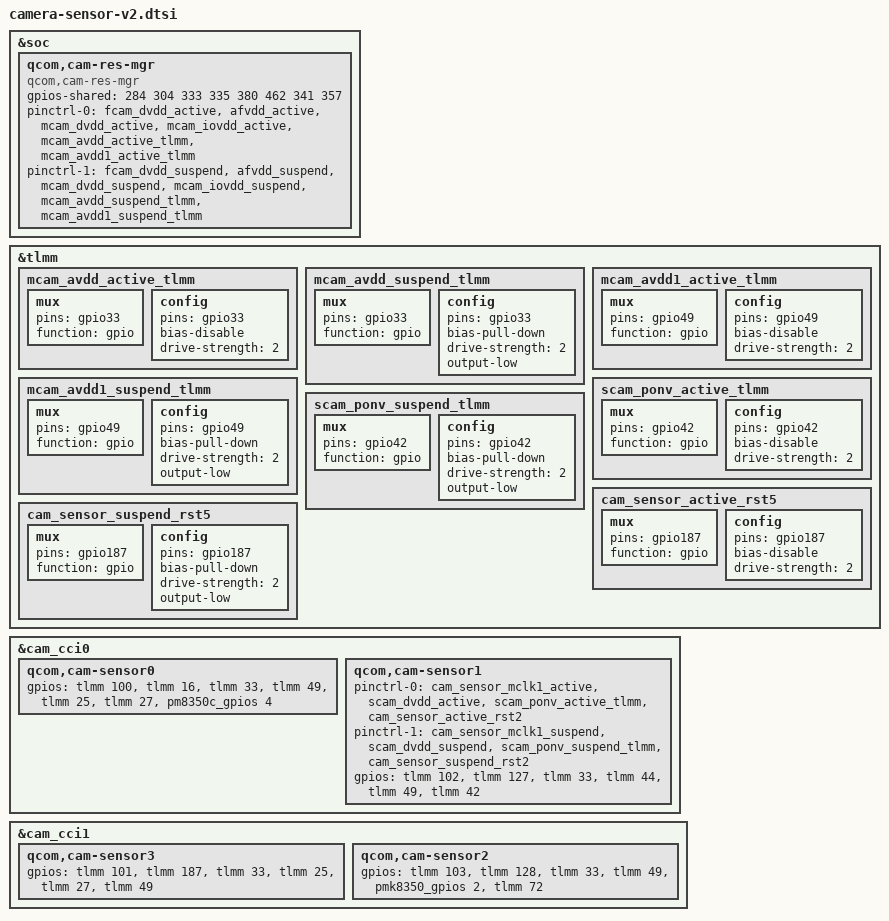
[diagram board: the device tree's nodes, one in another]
#include "camera-sensor-v1.dtsi"

&soc {
	qcom,cam-res-mgr {
		compatible = "qcom,cam-res-mgr";
		status = "ok";
		gpios-shared = <284 304 333 335 380 462 341 357>;
		pinctrl-names = "cam_active", "cam_suspend";
		pinctrl-0 = <&fcam_dvdd_active
					&afvdd_active
					&mcam_dvdd_active
					&mcam_iovdd_active
					&mcam_avdd_active_tlmm
					&mcam_avdd1_active_tlmm>;
		pinctrl-1 = <&fcam_dvdd_suspend
					&afvdd_suspend
					&mcam_dvdd_suspend
					&mcam_iovdd_suspend
					&mcam_avdd_suspend_tlmm
					&mcam_avdd1_suspend_tlmm>;
	};
};

&tlmm {
	mcam_avdd_active_tlmm: mcam_avdd_active_tlmm {
		mux {
			pins = "gpio33";
			function = "gpio";
		};

		config {
			pins = "gpio33";
			bias-disable; /* No PULL */
			drive-strength = <2>; /* 2 MA */
		};
	};

	mcam_avdd_suspend_tlmm: mcam_avdd_suspend_tlmm {
		mux {
			pins = "gpio33";
			function = "gpio";
		};

		config {
			pins = "gpio33";
			bias-pull-down; /* PULL DOWN */
			drive-strength = <2>; /* 2 MA */
			output-low;
		};
	};
	mcam_avdd1_active_tlmm: mcam_avdd1_active_tlmm {
		mux {
			pins = "gpio49";
			function = "gpio";
		};

		config {
			pins = "gpio49";
			bias-disable; /* No PULL */
			drive-strength = <2>; /* 2 MA */
		};
	};

	mcam_avdd1_suspend_tlmm: mcam_avdd1_suspend_tlmm {
		mux {
			pins = "gpio49";
			function = "gpio";
		};

		config {
			pins = "gpio49";
			bias-pull-down; /* PULL DOWN */
			drive-strength = <2>; /* 2 MA */
			output-low;
		};
	};

	scam_ponv_active_tlmm: scam_ponv_active_tlmm {
		mux {
			pins = "gpio42";
			function = "gpio";
		};

		config {
			pins = "gpio42";
			bias-disable; /* No PULL */
			drive-strength = <2>; /* 2 MA */
		};
	};

	scam_ponv_suspend_tlmm: scam_ponv_suspend_tlmm {
		mux {
			pins = "gpio42";
			function = "gpio";
		};

		config {
			pins = "gpio42";
			bias-pull-down; /* PULL DOWN */
			drive-strength = <2>; /* 2 MA */
			output-low;
		};
	};
	cam_sensor_active_rst5 {
		/* RESET 5 */
		mux {
			pins = "gpio187";
			function = "gpio";
		};

		config {
			pins = "gpio187";
			bias-disable; /* No PULL */
			drive-strength = <2>; /* 2 MA */
		};
	};

	cam_sensor_suspend_rst5 {
		/* RESET 2 */
		mux {
			pins = "gpio187";
			function = "gpio";
		};

		config {
			pins = "gpio187";
			bias-pull-down; /* PULL DOWN */
			drive-strength = <2>; /* 2 MA */
			output-low;
		};
	};
};

&cam_cci0 {
	/* back main sensor */
	qcom,cam-sensor0 {
		gpios = <&tlmm 100 0>,
			<&tlmm 16 0>,
			<&tlmm 33 0>,
			<&tlmm 49 0>,
			<&tlmm 25 0>,
			<&tlmm 27 0>,
			<&pm8350c_gpios 4 0>;
		status = "ok";
	};

	/* back wide sensor */
	qcom,cam-sensor1 {
		pinctrl-0 = <&cam_sensor_mclk1_active
				&scam_dvdd_active
				&scam_ponv_active_tlmm
				&cam_sensor_active_rst2>;
		pinctrl-1 = <&cam_sensor_mclk1_suspend
				&scam_dvdd_suspend
				&scam_ponv_suspend_tlmm
				&cam_sensor_suspend_rst2>;
		gpios = <&tlmm 102 0>,
			<&tlmm 127 0>,
			<&tlmm 33 0>,
			<&tlmm 44 0>,
			<&tlmm 49 0>,
			<&tlmm 42 0>;
		status = "ok";
	};
};

&cam_cci1 {
	/* back tele sensor */
	qcom,cam-sensor3 {
		gpios = <&tlmm 101 0>,
			<&tlmm 187 0>,
			<&tlmm 33 0>,
			<&tlmm 25 0>,
			<&tlmm 27 0>,
			<&tlmm 49 0>;
		status = "ok";
	};
	/* front main sensor */
	qcom,cam-sensor2 {
		gpios = <&tlmm 103 0>,
			<&tlmm 128 0>,
			<&tlmm 33 0>,
			<&tlmm 49 0>,
			<&pmk8350_gpios 2 0>,
			<&tlmm 72 0>;
		status = "ok";
	};
};
